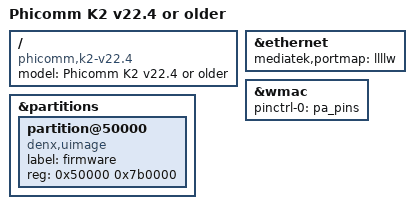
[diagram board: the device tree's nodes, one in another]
#include "mt7620a_phicomm_k2x.dtsi"

/ {
	compatible = "phicomm,k2-v22.4", "ralink,mt7620a-soc";
	model = "Phicomm K2 v22.4 or older";
};

&partitions {
	partition@50000 {
		compatible = "denx,uimage";
		label = "firmware";
		reg = <0x50000 0x7b0000>;
	};
};

&ethernet {
	mediatek,portmap = "llllw";
};

&wmac {
	pinctrl-names = "default";
	pinctrl-0 = <&pa_pins>;
};
